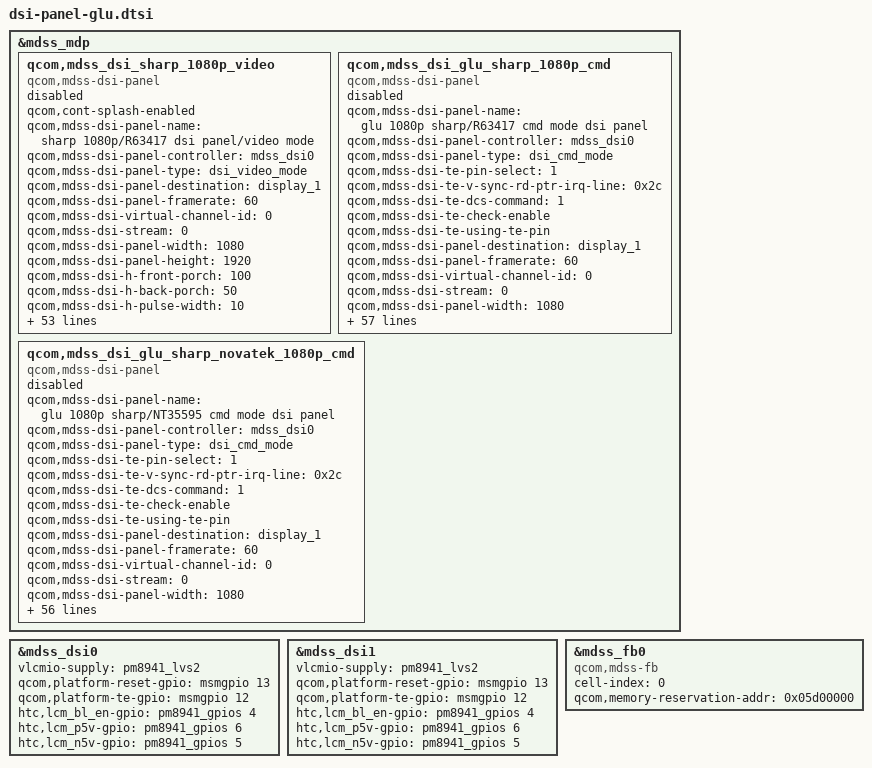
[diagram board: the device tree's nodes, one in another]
&mdss_mdp {
	qcom,mdss_dsi_sharp_1080p_video {
		compatible = "qcom,mdss-dsi-panel";
		status = "disable";
		qcom,cont-splash-enabled;
		qcom,mdss-dsi-panel-name = "sharp 1080p/R63417 dsi panel/video mode";
		qcom,mdss-dsi-panel-controller = <&mdss_dsi0>;
		qcom,mdss-dsi-panel-type = "dsi_video_mode";
		qcom,mdss-dsi-panel-destination = "display_1";
		qcom,mdss-dsi-panel-framerate = <60>;
		qcom,mdss-dsi-virtual-channel-id = <0>;
		qcom,mdss-dsi-stream = <0>;
		qcom,mdss-dsi-panel-width = <1080>;
		qcom,mdss-dsi-panel-height = <1920>;
		qcom,mdss-dsi-h-front-porch = <100>;
		qcom,mdss-dsi-h-back-porch = <50>;
		qcom,mdss-dsi-h-pulse-width = <10>;
		qcom,mdss-dsi-h-sync-skew = <0>;
		qcom,mdss-dsi-v-back-porch = <4>;
		qcom,mdss-dsi-v-front-porch = <4>;
		qcom,mdss-dsi-v-pulse-width = <2>;
		qcom,mdss-dsi-h-left-border = <0>;
		qcom,mdss-dsi-h-right-border = <0>;
		qcom,mdss-dsi-v-top-border = <0>;
		qcom,mdss-dsi-v-bottom-border = <0>;
		qcom,mdss-dsi-bpp = <24>;
		qcom,mdss-dsi-color-order = "rgb_swap_rgb";
		qcom,mdss-dsi-underflow-color = <0xff>;
		qcom,mdss-dsi-border-color = <0>;
		qcom,mdss-dsi-on-command = [ 29 01 00 00 00 00 02 b0 04 /* unlock_command */
				29 01 00 00 00 00 02 d6 01 /* Manufacture_Command */
				29 01 00 00 00 00 02 b3 14 /* Config to Video Mode */
				/* Common setting */
				29 01 00 00 00 00 18 CE 69 40 43 49 55 62 71
					82 94 A8 B9 CB DB E9 F5
					FC FF 04 0B 06 06 54 20
				/* still mode */
				29 01 00 00 00 00 07 B9 07 90 1E 10 1E 66
				/* move mode */
				29 01 00 00 00 00 07 BA 07 96 41 10 6E CC
				/* color enhancement */
				29 01 00 00 00 00 21 CA 01 02 9A A4 B8 B4
					B0 A4 08 28 05 87 B0 50
					01 FF 05 F8 0C 0C 50 40
					13 13 F0 08 10 10 3F 3F
					3F 3F
				39 01 00 00 00 00 02 53 04 /* pwm_enable */
				39 01 00 00 00 00 02 55 02 /* cabc mode */
				39 01 00 00 00 00 02 5E 0B /* cabc min */
				15 01 00 00 00 00 02 35 00 /* TE */
				/* 39 01 00 00 0a 00 02 29 00  display_on */
				39 01 00 00 78 00 02 11 00 /* exit_sleep */];
		qcom,mdss-dsi-off-command = [05 01 00 00 01 00 02 10 00
				05 01 00 00 30 00 02 28 00
				39 01 00 00 01 00 02 b0 04
				39 01 00 00 01 00 02 b0 01];
		qcom,mdss-dsi-on-command-state = "dsi_lp_mode";
		qcom,mdss-dsi-off-command-state = "dsi_hs_mode";

		qcom,mdss-dsi-h-sync-pulse = <0>;
		qcom,mdss-dsi-traffic-mode = "non_burst_sync_event";
		qcom,mdss-dsi-bllp-eof-power-mode;
		qcom,mdss-dsi-lane-map = "lane_map_0123";
		qcom,mdss-dsi-bllp-power-mode;
		qcom,mdss-dsi-lane-0-state;
		qcom,mdss-dsi-lane-1-state;
		qcom,mdss-dsi-lane-2-state;
		qcom,mdss-dsi-lane-3-state;
		qcom,mdss-dsi-panel-timings = [c3 40 33 00 57 51 35 42 52 03 04 00];
		qcom,mdss-dsi-t-clk-post = <0x02>;
		qcom,mdss-dsi-t-clk-pre = <0x2a>;
		qcom,mdss-dsi-bl-min-level = <1>;
		qcom,mdss-dsi-bl-max-level = <255>;
		qcom,mdss-dsi-dma-trigger = "trigger_sw";
		qcom,mdss-dsi-mdp-trigger = "none";
		qcom,mdss-dsi-bl-pmic-control-type = "bl_ctrl_dcs";

		qcom,display-on-cmds = [39 01 00 00 00 00 02 29 00];
		qcom,mdss-dsi-default-command-state = "dsi_hs_mode";
		qcom,mdss-pan-physical-width-dimension = <61>;
		qcom,mdss-pan-physical-height-dimension = <109>;
		qcom,mdss-shrink-pwm = <11 79 255>;
		qcom,mdss-pwm-ctl-type = <1>;
		htc,mdss-camera-blk = <177>;
		htc,cabc-off-cmds = [39 01 00 00 00 00 02 55 00];
		htc,cabc-ui-cmds = [39 01 00 00 00 00 02 55 02];
		htc,dimming-on-cmds = [39 01 00 00 00 00 02 53 0C];
		htc,panel-id=<0>;
	};

	qcom,mdss_dsi_glu_sharp_1080p_cmd {
		compatible = "qcom,mdss-dsi-panel";
		status = "disable";
		qcom,mdss-dsi-panel-name = "glu 1080p sharp/R63417 cmd mode dsi panel";
		qcom,mdss-dsi-panel-controller = <&mdss_dsi0>;

		qcom,mdss-dsi-panel-type = "dsi_cmd_mode";
		qcom,mdss-dsi-te-pin-select = <1>;
		qcom,mdss-dsi-te-v-sync-rd-ptr-irq-line = <0x2c>;
		qcom,mdss-dsi-te-dcs-command = <1>;
		qcom,mdss-dsi-te-check-enable;
		qcom,mdss-dsi-te-using-te-pin;

		qcom,mdss-dsi-panel-destination = "display_1";
		qcom,mdss-dsi-panel-framerate = <60>;
		qcom,mdss-dsi-virtual-channel-id = <0>;
		qcom,mdss-dsi-stream = <0>;
		qcom,mdss-dsi-panel-width = <1080>;
		qcom,mdss-dsi-panel-height = <1920>;
		qcom,mdss-dsi-h-front-porch = <100>;
		qcom,mdss-dsi-h-back-porch = <50>;
		qcom,mdss-dsi-h-pulse-width = <10>;
		qcom,mdss-dsi-h-sync-skew = <0>;
		qcom,mdss-dsi-v-back-porch = <4>;
		qcom,mdss-dsi-v-front-porch = <4>;
		qcom,mdss-dsi-v-pulse-width = <2>;
		qcom,mdss-dsi-h-left-border = <0>;
		qcom,mdss-dsi-h-right-border = <0>;
		qcom,mdss-dsi-v-top-border = <0>;
		qcom,mdss-dsi-v-bottom-border = <0>;
		qcom,mdss-dsi-bpp = <24>;
		qcom,mdss-dsi-color-order = "rgb_swap_rgb";
		qcom,mdss-dsi-underflow-color = <0xff>;
		qcom,mdss-dsi-border-color = <0>;
		qcom,mdss-dsi-on-command = [ 29 01 00 00 00 00 02 b0 04 /* unlock_command */
				29 01 00 00 00 00 02 d6 01 /* Manufacture_Command */
				/* Common setting */
				29 01 00 00 00 00 18 CE 69 40 43 49 55 62 71
					82 94 A8 B9 CB DB E9 F5
					FC FF 04 0B 06 06 54 20
				/* still mode */
				29 01 00 00 00 00 07 B9 07 90 1E 10 1E 66
				/* move mode */
				29 01 00 00 00 00 07 BA 07 96 41 10 6E CC
				/* color enhancement */
				29 01 00 00 00 00 21 CA 01 02 9A A4 B8 B4
					B0 A4 08 28 05 87 B0 50
					01 FF 05 F8 0C 0C 50 40
					13 13 F0 08 10 10 3F 3F
					3F 3F
				39 01 00 00 00 00 02 53 04 /* pwm_enable */
				39 01 00 00 00 00 02 55 02 /* cabc mode */
				39 01 00 00 00 00 02 5E 0B /* cabc min */
				15 01 00 00 00 00 02 35 00 /* TE */
				/* 39 01 00 00 00 00 02 29 00  display_on */
				39 01 00 00 78 00 02 11 00 /* exit_sleep */];
		qcom,mdss-dsi-off-command = [39 01 00 00 10 00 02 28 00
				39 01 00 00 40 00 02 10 00];
		qcom,mdss-dsi-on-command-state = "dsi_lp_mode";
		qcom,mdss-dsi-off-command-state = "dsi_hs_mode";
		qcom,mdss-dsi-h-sync-pulse = <1>;
		qcom,mdss-dsi-traffic-mode = "non_burst_sync_event";
		qcom,mdss-dsi-bllp-eof-power-mode;
		qcom,mdss-dsi-lane-map = "lane_map_0123";
		qcom,mdss-dsi-bllp-power-mode;
		qcom,mdss-dsi-lane-0-state;
		qcom,mdss-dsi-lane-1-state;
		qcom,mdss-dsi-lane-2-state;
		qcom,mdss-dsi-lane-3-state;
		qcom,mdss-dsi-panel-timings =  [c3 40 33 00 57 51 35 42 52 03 04 00];
		qcom,mdss-dsi-t-clk-post = <0x02>;
		qcom,mdss-dsi-t-clk-pre = <0x2a>;
		qcom,mdss-dsi-bl-min-level = <1>;
		qcom,mdss-dsi-bl-max-level = <255>;
		qcom,mdss-dsi-dma-trigger = "trigger_sw";
		qcom,mdss-dsi-mdp-trigger = "none";
		qcom,mdss-dsi-bl-pmic-control-type = "bl_ctrl_dcs";

		qcom,display-on-cmds = [39 01 00 00 00 00 02 29 00];
		qcom,mdss-dsi-default-command-state = "dsi_hs_mode";
		qcom,mdss-pan-physical-width-dimension = <64>;
		qcom,mdss-pan-physical-height-dimension = <114>;
		qcom,mdss-shrink-pwm = <11 79 255>;
		qcom,mdss-pwm-ctl-type = <1>;
		htc,mdss-camera-blk = <177>;
		htc,cabc-off-cmds = [39 01 00 00 00 00 02 55 00];
		htc,cabc-ui-cmds = [39 01 00 00 00 00 02 55 02];
		htc,dimming-on-cmds = [39 01 00 00 00 00 02 53 0C];
		htc,panel-id=<0>;
	};

	qcom,mdss_dsi_glu_sharp_novatek_1080p_cmd {
		compatible = "qcom,mdss-dsi-panel";
		status = "disable";
		qcom,mdss-dsi-panel-name = "glu 1080p sharp/NT35595 cmd mode dsi panel";
		qcom,mdss-dsi-panel-controller = <&mdss_dsi0>;

		qcom,mdss-dsi-panel-type = "dsi_cmd_mode";
		qcom,mdss-dsi-te-pin-select = <1>;
		qcom,mdss-dsi-te-v-sync-rd-ptr-irq-line = <0x2c>;
		qcom,mdss-dsi-te-dcs-command = <1>;
		qcom,mdss-dsi-te-check-enable;
		qcom,mdss-dsi-te-using-te-pin;

		qcom,mdss-dsi-panel-destination = "display_1";
		qcom,mdss-dsi-panel-framerate = <60>;
		qcom,mdss-dsi-virtual-channel-id = <0>;
		qcom,mdss-dsi-stream = <0>;
		qcom,mdss-dsi-panel-width = <1080>;
		qcom,mdss-dsi-panel-height = <1920>;
		qcom,mdss-dsi-h-front-porch = <100>;
		qcom,mdss-dsi-h-back-porch = <50>;
		qcom,mdss-dsi-h-pulse-width = <10>;
		qcom,mdss-dsi-h-sync-skew = <0>;
		qcom,mdss-dsi-v-back-porch = <4>;
		qcom,mdss-dsi-v-front-porch = <4>;
		qcom,mdss-dsi-v-pulse-width = <2>;
		qcom,mdss-dsi-h-left-border = <0>;
		qcom,mdss-dsi-h-right-border = <0>;
		qcom,mdss-dsi-v-top-border = <0>;
		qcom,mdss-dsi-v-bottom-border = <0>;
		qcom,mdss-dsi-bpp = <24>;
		qcom,mdss-dsi-color-order = "rgb_swap_rgb";
		qcom,mdss-dsi-underflow-color = <0xff>;
		qcom,mdss-dsi-border-color = <0>;
		qcom,mdss-dsi-on-command = [ 29 01 00 00 00 00 02 bb 10	/*Setting MIPI Mode, 03--video, 10--command*/
		29 01 00 00 00 00 02 b0 03	/* CRC control, 00--on, 03--off*/
		39 01 00 00 00 00 02 53 24	/* pwm_enable */
		15 01 00 00 00 00 02 35 00	/* TE */
		39 01 00 00 01 00 02 FF 24	/* Go to CMD2 P4 */
		39 01 00 00 00 00 02 C5 30	/* Set LEDPWM pin output LEDPWM */
		39 01 00 00 00 00 02 C4 24
		39 01 00 00 00 00 02 FB 01	/* Set CMD2 P0 non-reload*/
		39 01 00 00 01 00 02 FF 23	/* CMD2 page3  */
		39 01 00 00 00 00 02 00 02	/* Set DMCT=1, Manual dimming functions  */
		39 01 00 00 00 00 02 05 12	/* still mode, movie mode dimming  */
		39 01 00 00 00 00 02 01 80
		39 01 00 00 00 00 02 FB 01	/* MTP do not reload */
		39 01 00 00 00 00 02 46 A4	/* PWM duty cont for 20kHz  */
		39 01 00 00 00 00 02 08 05	/* PWMDIV[7:0] for PWM frequency  */
		39 01 00 00 00 00 02 5E 0B	/* PWM min setting */
		39 01 00 00 00 00 02 17 FF	/* PWM still mode PWM */
		39 01 00 00 00 00 02 18 FA	/* PWM still mode PWM */
		39 01 00 00 00 00 02 19 F8	/* PWM still mode PWM */
		39 01 00 00 00 00 02 1A F5	/* PWM still mode PWM */
		39 01 00 00 00 00 02 1B EE	/* PWM still mode PWM */
		39 01 00 00 00 00 02 1C E1	/* PWM still mode PWM */
		39 01 00 00 00 00 02 1D D5	/* PWM still mode PWM */
		39 01 00 00 00 00 02 1E CD	/* PWM still mode PWM */
		39 01 00 00 00 00 02 1F B9	/* PWM still mode PWM */
		39 01 00 00 00 00 02 20 B4	/* PWM still mode PWM */
		39 01 00 00 00 00 02 21 FF	/* PWM movie mode PWM */
		39 01 00 00 00 00 02 22 FA	/* PWM movie mode PWM */
		39 01 00 00 00 00 02 23 F5	/* PWM movie mode PWM */
		39 01 00 00 00 00 02 24 EB	/* PWM movie mode PWM */
		39 01 00 00 00 00 02 25 E1	/* PWM movie mode PWM */
		39 01 00 00 00 00 02 26 C8	/* PWM movie mode PWM */
		39 01 00 00 00 00 02 27 AA	/* PWM movie mode PWM */
		39 01 00 00 00 00 02 28 96	/* PWM movie mode PWM */
		39 01 00 00 00 00 02 29 73	/* PWM movie mode PWM */
		39 01 00 00 00 00 02 2A 66	/* PWM movie mode PWM */
		39 01 00 00 00 00 02 09 0A	/* PWM still mode Gamma curve compensation */
		39 01 00 00 00 00 02 0A 0B	/* PWM still mode Gamma curve compensation */
		39 01 00 00 00 00 02 0B 10	/* PWM still mode Gamma curve compensation */
		39 01 00 00 00 00 02 0C 10	/* PWM still mode Gamma curve compensation */
		39 01 00 00 00 00 02 0D 10	/* PWM still mode Gamma curve compensation */
		39 01 00 00 00 00 02 0E 10	/* PWM still mode Gamma curve compensation */
		39 01 00 00 00 00 02 0F 10	/* PWM still mode Gamma curve compensation */
		39 01 00 00 00 00 02 10 17	/* PWM still mode Gamma curve compensation */
		39 01 00 00 00 00 02 11 18	/* PWM still mode Gamma curve compensation */
		39 01 00 00 00 00 02 12 20	/* PWM still mode Gamma curve compensation */
		39 01 00 00 00 00 02 33 20	/* PWM still Movie Gamma curve compensation */
		39 01 00 00 01 00 02 FF 22	/* CMD2 Page2 */
		39 01 00 00 00 00 02 00 00	/* IE related setting */
		39 01 00 00 00 00 02 01 04
		39 01 00 00 00 00 02 02 08
		39 01 00 00 00 00 02 03 0C
		39 01 00 00 00 00 02 04 10
		39 01 00 00 00 00 02 05 14
		39 01 00 00 00 00 02 06 18
		39 01 00 00 00 00 02 07 20
		39 01 00 00 00 00 02 08 24
		39 01 00 00 00 00 02 09 28
		39 01 00 00 00 00 02 0A 30
		39 01 00 00 00 00 02 0B 38
		39 01 00 00 00 00 02 0C 38
		39 01 00 00 00 00 02 0D 30
		39 01 00 00 00 00 02 0E 28
		39 01 00 00 00 00 02 0F 20
		39 01 00 00 00 00 02 10 10
		39 01 00 00 00 00 02 11 00
		39 01 00 00 00 00 02 12 00
		39 01 00 00 00 00 02 13 00
		39 01 00 00 00 00 02 1B 00
		39 01 00 00 00 00 02 1C 04
		39 01 00 00 00 00 02 1D 08
		39 01 00 00 00 00 02 1E 0C
		39 01 00 00 00 00 02 1F 10
		39 01 00 00 00 00 02 20 14
		39 01 00 00 00 00 02 21 18
		39 01 00 00 00 00 02 22 20
		39 01 00 00 00 00 02 23 18
		39 01 00 00 00 00 02 24 10
		39 01 00 00 00 00 02 25 08
		39 01 00 00 00 00 02 26 00
		39 01 00 00 00 00 02 27 00
		39 01 00 00 00 00 02 28 00
		39 01 00 00 00 00 02 29 00
		39 01 00 00 00 00 02 2A 00
		39 01 00 00 00 00 02 2B 00
		39 01 00 00 00 00 02 2F 00
		39 01 00 00 00 00 02 30 00
		39 01 00 00 00 00 02 31 00
		39 01 00 00 00 00 02 32 9C
		39 01 00 00 00 00 02 33 9C
		39 01 00 00 00 00 02 34 9C
		39 01 00 00 00 00 02 35 00
		39 01 00 00 00 00 02 36 02
		39 01 00 00 00 00 02 37 04
		39 01 00 00 00 00 02 38 06
		39 01 00 00 00 00 02 39 08
		39 01 00 00 00 00 02 3A 0A
		39 01 00 00 00 00 02 3B 0C
		39 01 00 00 00 00 02 3F 0E
		39 01 00 00 00 00 02 40 12
		39 01 00 00 00 00 02 41 16
		39 01 00 00 00 00 02 42 16
		39 01 00 00 00 00 02 43 12
		39 01 00 00 00 00 02 44 0E
		39 01 00 00 00 00 02 45 0C
		39 01 00 00 00 00 02 46 0A
		39 01 00 00 00 00 02 47 08
		39 01 00 00 00 00 02 48 06
		39 01 00 00 00 00 02 49 04
		39 01 00 00 00 00 02 4A 02
		39 01 00 00 00 00 02 4B 00
		39 01 00 00 00 00 02 4C 9C
		39 01 00 00 00 00 02 1A 01
		39 01 00 00 00 00 02 53 00
		39 01 00 00 00 00 02 54 00
		39 01 00 00 00 00 02 55 00
		39 01 00 00 00 00 02 56 00
		39 01 00 00 00 00 02 68 01
		39 01 00 00 00 00 02 14 10
		39 01 00 00 00 00 02 4D 00
		39 01 00 00 00 00 02 58 12
		39 01 00 00 00 00 02 59 0E
		39 01 00 00 00 00 02 64 2F
		39 01 00 00 00 00 02 65 02
		39 01 00 00 00 00 02 69 02
		39 01 00 00 00 00 02 FB 01
		39 01 00 00 01 00 02 FF 10	/* Return CMD1  */
		39 01 00 00 00 00 02 55 82	/* IE slight level */
		39 01 00 00 78 00 02 11 00	/* exit_sleep */
		/* 39 01 00 00 28 00 02 29 00  display_on */];
		qcom,mdss-dsi-off-command = [39 01 00 00 10 00 02 28 00
				       39 01 00 00 40 00 02 10 00];
		qcom,mdss-dsi-on-command-state = "dsi_lp_mode";
		qcom,mdss-dsi-off-command-state = "dsi_hs_mode";
		qcom,mdss-dsi-h-sync-pulse = <1>;
		qcom,mdss-dsi-traffic-mode = "non_burst_sync_event";
		qcom,mdss-dsi-bllp-eof-power-mode;
		qcom,mdss-dsi-lane-map = "lane_map_0123";
		qcom,mdss-dsi-bllp-power-mode;
		qcom,mdss-dsi-lane-0-state;
		qcom,mdss-dsi-lane-1-state;
		qcom,mdss-dsi-lane-2-state;
		qcom,mdss-dsi-lane-3-state;
		qcom,mdss-dsi-panel-timings =  [c3 40 33 00 57 51 35 42 52 03 04 00];
		qcom,mdss-dsi-t-clk-post = <0x02>;
		qcom,mdss-dsi-t-clk-pre = <0x2a>;
		qcom,mdss-dsi-bl-min-level = <1>;
		qcom,mdss-dsi-bl-max-level = <255>;
		qcom,mdss-dsi-dma-trigger = "trigger_sw";
		qcom,mdss-dsi-mdp-trigger = "none";
		qcom,mdss-dsi-bl-pmic-control-type = "bl_ctrl_dcs";

		qcom,display-on-cmds = [39 01 00 00 00 00 02 29 00];
		qcom,mdss-dsi-default-command-state = "dsi_hs_mode";
		qcom,mdss-pan-physical-width-dimension = <64>;
		qcom,mdss-pan-physical-height-dimension = <114>;
		qcom,mdss-shrink-pwm = <11 79 255>;
		htc,mdss-camera-blk = <177>;
		htc,cabc-off-cmds = [39 01 00 00 00 00 02 55 00];
		htc,cabc-ui-cmds = [39 01 00 00 00 00 02 55 82];
		htc,dimming-on-cmds = [39 01 00 00 00 00 02 53 2C];
		htc,panel-id=<1>;
	};
};

&mdss_dsi0 {
	vlcmio-supply = <&pm8941_lvs2>; /* lcm 1v8 */
	qcom,platform-reset-gpio = <&msmgpio 13 0>;
	qcom,platform-te-gpio = <&msmgpio 12 0>;
	htc,lcm_bl_en-gpio = <&pm8941_gpios 4 0>;
	htc,lcm_p5v-gpio = <&pm8941_gpios 6 0>;
	htc,lcm_n5v-gpio = <&pm8941_gpios 5 0>;
};

&mdss_dsi1 {
	vlcmio-supply = <&pm8941_lvs2>; /* lcm 1v8 */
	qcom,platform-reset-gpio = <&msmgpio 13 0>;
	qcom,platform-te-gpio = <&msmgpio 12 0>;
	htc,lcm_bl_en-gpio = <&pm8941_gpios 4 0>;
	htc,lcm_p5v-gpio = <&pm8941_gpios 6 0>;
	htc,lcm_n5v-gpio = <&pm8941_gpios 5 0>;
};

&mdss_fb0 {
	cell-index = <0>;
	compatible = "qcom,mdss-fb";
	/* qcom,memory-reservation-type = "EBI1";
	qcom,memory-reservation-size = <0x1800000>; */ /* FB size for dynamic allocation */
	qcom,memory-reservation-addr = <0x05d00000>;
};
